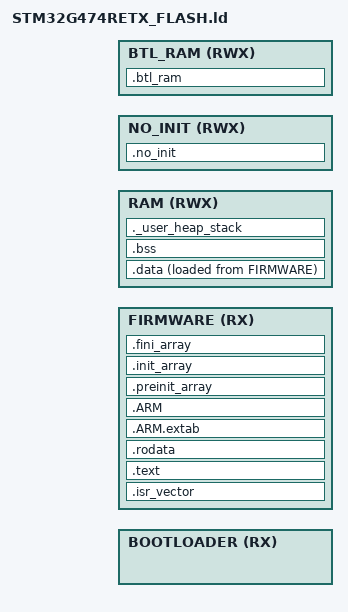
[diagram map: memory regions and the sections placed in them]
/*
******************************************************************************
**
** @file        : LinkerScript.ld
**
** @author      : Auto-generated by STM32CubeIDE
**
** @brief       : Linker script for STM32G474RETx Device from STM32G4 series
**                      512Kbytes FLASH
**                      128Kbytes RAM
**
**                Set heap size, stack size and stack location according
**                to application requirements.
**
**                Set memory bank area and size if external memory is used
**
**  Target      : STMicroelectronics STM32
**
**  Distribution: The file is distributed as is, without any warranty
**                of any kind.
**
******************************************************************************
** @attention
**
** Copyright (c) 2023 STMicroelectronics.
** All rights reserved.
**
** This software is licensed under terms that can be found in the LICENSE file
** in the root directory of this software component.
** If no LICENSE file comes with this software, it is provided AS-IS.
**
******************************************************************************
*/

INCLUDE ../MemoryAddress.lds

/* Entry Point */
ENTRY(Reset_Handler)

_Min_Heap_Size = 0x200; /* required amount of heap */
_Min_Stack_Size = 0x400; /* required amount of stack */

/* Memories definition */
/*
 *	BOOTLOADER region is for the BootLoader firmware
 *	FIRMWARE region is for the application firmware
 *	RAM region is the RAM
 *  NO_INIT region is a non initialized section of RAM to keep data after a watchdog or hardfault reboot
 *	BTL_RAM region is a non initialized section of RAM to exchange data between bootlader and application firmwares
 */

MEMORY
{
	BOOTLOADER (RX)	:	ORIGIN = _bootloader_start_addr, LENGTH = _bootloader_length
	FIRMWARE (RX)		: ORIGIN = _main_app_start_address, LENGTH = _firmware_length
	RAM (RWX) : ORIGIN = _ram_start_addr, LENGTH = _ram_length
  NO_INIT (RWX)	: ORIGIN = _no_init_memory_address, LENGTH = _no_init_memory_length
	BTL_RAM (RWX)		: ORIGIN = _shared_memory_address, LENGTH = _shared_memory_length
}

/* alis the FIRMWARE region with FLASH */
REGION_ALIAS("FLASH", FIRMWARE );

/* Sections */
SECTIONS
{
  /* The startup code into "FLASH" Rom type memory */
  .isr_vector :
  {
    . = ALIGN(4);
    KEEP(*(.isr_vector)) /* Startup code */
    . = ALIGN(4);
  } >FLASH

  /* The program code and other data into "FLASH" Rom type memory */
  .text :
  {
    . = ALIGN(4);
    *(.text)           /* .text sections (code) */
    *(.text*)          /* .text* sections (code) */
    *(.glue_7)         /* glue arm to thumb code */
    *(.glue_7t)        /* glue thumb to arm code */
    *(.eh_frame)

    KEEP (*(.init))
    KEEP (*(.fini))

    . = ALIGN(4);
    _etext = .;        /* define a global symbols at end of code */
  } >FLASH

  /* Constant data into "FLASH" Rom type memory */
  .rodata :
  {
    . = ALIGN(4);
    *(.rodata)         /* .rodata sections (constants, strings, etc.) */
    *(.rodata*)        /* .rodata* sections (constants, strings, etc.) */
    . = ALIGN(4);
  } >FLASH

  .ARM.extab   : {
    . = ALIGN(4);
    *(.ARM.extab* .gnu.linkonce.armextab.*)
    . = ALIGN(4);
  } >FLASH

  .ARM : {
    . = ALIGN(4);
    __exidx_start = .;
    *(.ARM.exidx*)
    __exidx_end = .;
    . = ALIGN(4);
  } >FLASH

  .preinit_array     :
  {
    . = ALIGN(4);
    PROVIDE_HIDDEN (__preinit_array_start = .);
    KEEP (*(.preinit_array*))
    PROVIDE_HIDDEN (__preinit_array_end = .);
    . = ALIGN(4);
  } >FLASH

  .init_array :
  {
    . = ALIGN(4);
    PROVIDE_HIDDEN (__init_array_start = .);
    KEEP (*(SORT(.init_array.*)))
    KEEP (*(.init_array*))
    PROVIDE_HIDDEN (__init_array_end = .);
    . = ALIGN(4);
  } >FLASH

  .fini_array :
  {
    . = ALIGN(4);
    PROVIDE_HIDDEN (__fini_array_start = .);
    KEEP (*(SORT(.fini_array.*)))
    KEEP (*(.fini_array*))
    PROVIDE_HIDDEN (__fini_array_end = .);
    . = ALIGN(4);
  } >FLASH

  /* Used by the startup to initialize data */
  _sidata = LOADADDR(.data);

  /* Initialized data sections into "RAM" Ram type memory */
  .data :
  {
    . = ALIGN(4);
    _sdata = .;        /* create a global symbol at data start */
    *(.data)           /* .data sections */
    *(.data*)          /* .data* sections */
    *(.RamFunc)        /* .RamFunc sections */
    *(.RamFunc*)       /* .RamFunc* sections */

    . = ALIGN(4);
    _edata = .;        /* define a global symbol at data end */

  } >RAM AT> FLASH

  /* section RAM non initialisee et partagee avec le bootloader */
  .btl_ram (NOLOAD) :
  {
    . = ALIGN(4);
    _sbtl_ram = .;       /* create a global symbol at ccmram start */
    __btl_ram_start__ = _sbtl_ram;
    *(.btl_ram.BOOT_VERSION)
		*(.btl_ram.BOOT_MODE)
		*(.btl_ram.BOOT_HARDFAULT_PC)
		*(.btl_ram.BOOT_HARDFAULT_LR)
    *(.btl_ram*)
    
    . = ALIGN(4);
    _ebtl_ram = .;       /* create a global symbol at ccmram end */
    __btl_ram_end__ = _ebtl_ram;
  } >BTL_RAM

  /* section RAM non initialisee et partagee avec le bootloader */
  .no_init (NOLOAD) :
  {
    . = ALIGN(4);
    _sno_init = .;       /* create a global symbol at ccmram start */
    __no_init_start__ = _sno_init;
    *(.no_init*)
    
    . = ALIGN(4);
    _eno_init = .;       /* create a global symbol at ccmram end */
    __no_init_end__ = _eno_init;
  } >NO_INIT

  /* Uninitialized data section into "RAM" Ram type memory */
  . = ALIGN(4);
  .bss :
  {
    /* This is used by the startup in order to initialize the .bss section */
    _sbss = .;         /* define a global symbol at bss start */
    __bss_start__ = _sbss;
    *(.bss)
    *(.bss*)
    *(COMMON)

    . = ALIGN(4);
    _ebss = .;         /* define a global symbol at bss end */
    __bss_end__ = _ebss;
  } >RAM

  /* User_heap_stack section, used to check that there is enough "RAM" Ram  type memory left */
  ._user_heap_stack :
  {
    . = ALIGN(8);
    PROVIDE ( end = . );
    PROVIDE ( _end = . );
    . = . + _Min_Heap_Size;
    . = . + _Min_Stack_Size;
    . = ALIGN(8);
  } >RAM

  /* Remove information from the compiler libraries */
  /DISCARD/ :
  {
    libc.a ( * )
    libm.a ( * )
    libgcc.a ( * )
  }

  .ARM.attributes 0 : { *(.ARM.attributes) }
}
